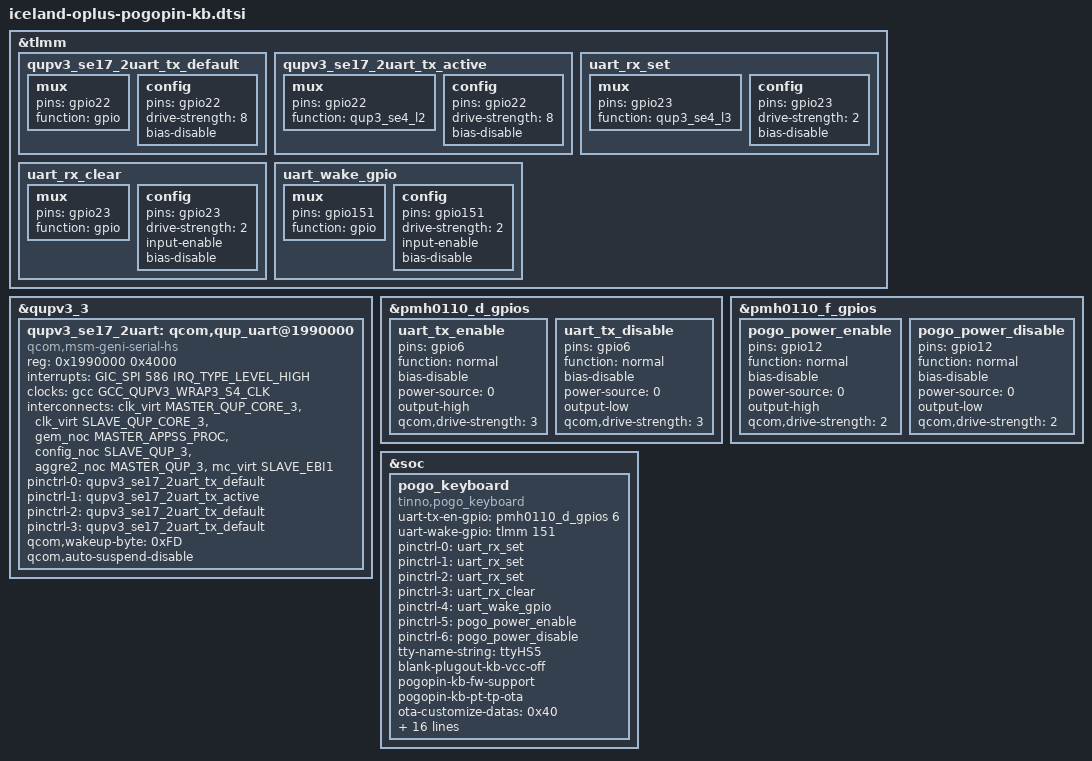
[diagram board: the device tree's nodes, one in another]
#include <dt-bindings/interrupt-controller/irq.h>
#include <dt-bindings/interrupt-controller/arm-gic.h>
#include <dt-bindings/interconnect/qcom,canoe.h>

&tlmm {
	qupv3_se17_2uart_tx_default: qupv3_se17_2uart_tx_default {
		mux {
			pins = "gpio22";
			function = "gpio";
		};

		config {
			pins = "gpio22";
			drive-strength = <8>;
			bias-disable;
		};
	};

	qupv3_se17_2uart_tx_active: qupv3_se17_2uart_tx_active {
		mux {
			pins = "gpio22";
			function = "qup3_se4_l2";
		};

		config {
			pins = "gpio22";
			drive-strength = <8>;
			bias-disable;
		};
	};
};

&qupv3_3 {
	qupv3_se17_2uart: qcom,qup_uart@1990000 {
		compatible = "qcom,msm-geni-serial-hs";
		reg = <0x1990000 0x4000>;
		reg-names = "se_phys";
		interrupts = <GIC_SPI 586 IRQ_TYPE_LEVEL_HIGH>;
		clock-names = "se-clk";
		clocks = <&gcc GCC_QUPV3_WRAP3_S4_CLK>;
		interconnect-names = "qup-core", "qup-config", "qup-memory";
		interconnects =
		<&clk_virt MASTER_QUP_CORE_3 &clk_virt SLAVE_QUP_CORE_3>,
		<&gem_noc MASTER_APPSS_PROC &config_noc SLAVE_QUP_3>,
		<&aggre2_noc MASTER_QUP_3 &mc_virt  SLAVE_EBI1>;
		pinctrl-names = "default", "active", "sleep", "shutdown";
		pinctrl-0 = <&qupv3_se17_2uart_tx_default>;
		pinctrl-1 = <&qupv3_se17_2uart_tx_active>;
		pinctrl-2 = <&qupv3_se17_2uart_tx_default>;
		pinctrl-3 = <&qupv3_se17_2uart_tx_default>;
		qcom,wakeup-byte = <0xFD>;
		qcom,auto-suspend-disable;
		status = "ok";
	};
};

&pmh0110_d_gpios {
	uart_tx_enable: uart_tx_enable {
		pins = "gpio6";
		function = "normal";
		bias-disable;
		power-source = <0>;
		output-high;
		qcom,drive-strength = <3>;
	};
	uart_tx_disable: uart_tx_disable {
		pins = "gpio6";
		function = "normal";
		bias-disable;
		power-source = <0>;
		output-low;
		qcom,drive-strength = <3>;
	};
};

&pmh0110_f_gpios {
	pogo_power_enable: pogo_power_enable {
		pins = "gpio12";
		function = "normal";
		bias-disable;
		power-source = <0>;
		output-high;
		qcom,drive-strength = <2>;
	};
	pogo_power_disable: pogo_power_disable {
		pins = "gpio12";
		function = "normal";
		bias-disable;
		power-source = <0>;
		output-low;
		qcom,drive-strength = <2>;
	};
};

&tlmm {
	uart_rx_set: uart_rx_set {
		mux {
			pins = "gpio23";
			function = "qup3_se4_l3";
		};

		config {
			pins = "gpio23";
			drive-strength = <2>;
			bias-disable;
		};
	};

	uart_rx_clear: uart_rx_clear {
		mux {
			pins = "gpio23";
			function = "gpio";
		};

		config {
			pins = "gpio23";
			drive-strength = <2>;
			input-enable;
			bias-disable;
		};
	};

	uart_wake_gpio: uart_wake_gpio {
		mux {
			pins = "gpio151";
			function = "gpio";
		};

		config {
			pins = "gpio151";
			drive-strength = <2>;
			input-enable;
			bias-disable;
		};
	};
};

&soc {
	pogo_keyboard {
		compatible = "tinno,pogo_keyboard";
		status = "ok";

		uart-tx-en-gpio = <&pmh0110_d_gpios 6 0x00>;
		uart-wake-gpio = <&tlmm 151 0x00>;

		pinctrl-names = "default", "sleep", "uart_rx_set", "uart_rx_clear", "uart_wake_gpio", "pogo_power_enable", "pogo_power_disable";
		pinctrl-0 = <&uart_rx_set>;
		pinctrl-1 = <&uart_rx_set>;
		pinctrl-2 = <&uart_rx_set>;
		pinctrl-3 = <&uart_rx_clear>;
		pinctrl-4 = <&uart_wake_gpio>;
		pinctrl-5 = <&pogo_power_enable>;
		pinctrl-6 = <&pogo_power_disable>;

		tty-name-string = "ttyHS5";
		blank-plugout-kb-vcc-off;

		pogopin-kb-fw-support;
		pogopin-kb-pt-tp-ota;
		/*dfu_fwinfo_start_addr*/
		ota-customize-datas = <0x40>;
		ota-firmware-name = "POGOPIN_KB.bin";

		keyboard-name-strings-enc =
			"iceland keyboard",
			"iceland-O keyboard",
			"iceland-O keyboard";
		keyboard-ble-name-strings-enc =
			"iceland keyboard",
			"iceland-O keyboard",
			"iceland-O keyboard";

		keyboard-name-strings =
			"OPPO Pad 5 Pro Smart Keyboard",
			"OnePlus Pad 3 Pro Smart Keyboard",
			"OnePlus Pad 4 Smart Keyboard";
		keyboard-ble-name-strings =
			"OPPO Pad 5 Pro Smart Keyboard",
			"OnePlus Pad 3 Pro Smart Keyboard",
			"OnePlus Pad 4 Smart Keyboard";

		touchpad-xy-max = <2560 1440>;
		touchpad-xy-resolution = <24 25>;
	};
};
